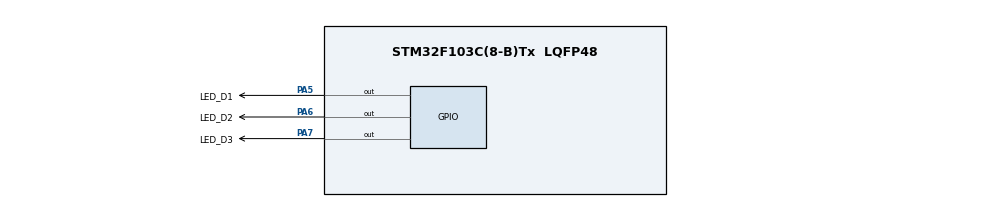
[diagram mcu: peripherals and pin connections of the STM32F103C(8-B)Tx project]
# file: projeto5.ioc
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Mcu.Family=STM32F1
Mcu.Name=STM32F103C(8-B)Tx
Mcu.Package=LQFP48
NVIC.PriorityGroup=NVIC_PRIORITYGROUP_4
NVIC.TIM1_BRK_IRQn=true\:0\:0\:false\:false\:true\:true\:true
NVIC.TIM1_UP_IRQn=true\:0\:0\:false\:false\:true\:true\:true
NVIC.TIM2_IRQn=true\:0\:0\:false\:false\:true\:true\:true
NVIC.TIM3_IRQn=true\:0\:0\:false\:false\:true\:true\:true
PA13.Mode=Serial_Wire
PA13.Signal=SYS_JTMS-SWDIO
PA14.Mode=Serial_Wire
PA14.Signal=SYS_JTCK-SWCLK
PA5.GPIO_Label=LED_D1
PA5.Signal=GPIO_Output
PA6.GPIO_Label=LED_D2
PA6.Signal=GPIO_Output
PA7.GPIO_Label=LED_D3
PA7.Signal=GPIO_Output
ProjectManager.HeapSize=0x200
ProjectManager.StackSize=0x400
ProjectManager.TargetToolchain=SW4STM32
RCC.APB1Freq_Value=8000000
RCC.APB2Freq_Value=8000000
TIM1.Period=9999
TIM1.Prescaler=799
TIM2.Period=9999
TIM2.Prescaler=1599
TIM3.Period=8000
TIM3.Prescaler=3199
VP_TIM1_VS_ClockSourceINT.Mode=Internal
VP_TIM2_VS_ClockSourceINT.Mode=Internal
VP_TIM3_VS_ClockSourceINT.Mode=Internal
board=custom

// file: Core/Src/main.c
/* USER CODE BEGIN Header */
/**
  ******************************************************************************
  * @file           : main.c
  * @brief          : Main program body
  ******************************************************************************
  * @attention
  *
  * <h2><center>&copy; Copyright (c) 2021 STMicroelectronics.
  * All rights reserved.</center></h2>
  *
  * This software component is licensed by ST under BSD 3-Clause license,
  * the "License"; You may not use this file except in compliance with the
  * License. You may obtain a copy of the License at:
  *                        opensource.org/licenses/BSD-3-Clause
  *
  ******************************************************************************
  */
/* USER CODE END Header */
#include "main.h"

TIM_HandleTypeDef htim1;
TIM_HandleTypeDef htim2;
TIM_HandleTypeDef htim3;

void SystemClock_Config(void);
static void MX_GPIO_Init(void);
static void MX_TIM1_Init(void);
static void MX_TIM2_Init(void);
static void MX_TIM3_Init(void);

int main(void)
{

  /* MCU Configuration--------------------------------------------------------*/

  /* Reset of all peripherals, Initializes the Flash interface and the Systick. */
  HAL_Init();

  /* Configure the system clock */
  SystemClock_Config();

  /* USER CODE BEGIN SysInit */
  HAL_GPIO_TogglePin(GPIOA, LED_D1_Pin);
  /* USER CODE END SysInit */

  /* Initialize all configured peripherals */
  MX_GPIO_Init();
  MX_TIM1_Init();
  MX_TIM2_Init();
  MX_TIM3_Init();
  /* USER CODE BEGIN 2 */
  HAL_TIM_Base_Start_IT(&htim3);
  HAL_TIM_Base_Start_IT(&htim2);
  HAL_TIM_Base_Start_IT(&htim1);
  /* USER CODE END 2 */

  /* Infinite loop */
  while (1)
  {

  }
}

void SystemClock_Config(void)
{
  RCC_OscInitTypeDef RCC_OscInitStruct = {0};
  RCC_ClkInitTypeDef RCC_ClkInitStruct = {0};

  /** Initializes the RCC Oscillators according to the specified parameters
  * in the RCC_OscInitTypeDef structure.
  */
  RCC_OscInitStruct.OscillatorType = RCC_OSCILLATORTYPE_HSI;
  RCC_OscInitStruct.HSIState = RCC_HSI_ON;
  RCC_OscInitStruct.HSICalibrationValue = RCC_HSICALIBRATION_DEFAULT;
  RCC_OscInitStruct.PLL.PLLState = RCC_PLL_NONE;
  if (HAL_RCC_OscConfig(&RCC_OscInitStruct) != HAL_OK)
  {
    Error_Handler();
  }
  /** Initializes the CPU, AHB and APB buses clocks
  */
  RCC_ClkInitStruct.ClockType = RCC_CLOCKTYPE_HCLK|RCC_CLOCKTYPE_SYSCLK
                              |RCC_CLOCKTYPE_PCLK1|RCC_CLOCKTYPE_PCLK2;
  RCC_ClkInitStruct.SYSCLKSource = RCC_SYSCLKSOURCE_HSI;
  RCC_ClkInitStruct.AHBCLKDivider = RCC_SYSCLK_DIV1;
  RCC_ClkInitStruct.APB1CLKDivider = RCC_HCLK_DIV1;
  RCC_ClkInitStruct.APB2CLKDivider = RCC_HCLK_DIV1;

  if (HAL_RCC_ClockConfig(&RCC_ClkInitStruct, FLASH_LATENCY_0) != HAL_OK)
  {
    Error_Handler();
  }
}

static void MX_TIM1_Init(void)
{

  TIM_ClockConfigTypeDef sClockSourceConfig = {0};
  TIM_MasterConfigTypeDef sMasterConfig = {0};

  htim1.Instance = TIM1;
  htim1.Init.Prescaler = 799;
  htim1.Init.CounterMode = TIM_COUNTERMODE_UP;
  htim1.Init.Period = 9999;
  htim1.Init.ClockDivision = TIM_CLOCKDIVISION_DIV1;
  htim1.Init.RepetitionCounter = 0;
  htim1.Init.AutoReloadPreload = TIM_AUTORELOAD_PRELOAD_DISABLE;
  if (HAL_TIM_Base_Init(&htim1) != HAL_OK)
  {
    Error_Handler();
  }
  sClockSourceConfig.ClockSource = TIM_CLOCKSOURCE_INTERNAL;
  if (HAL_TIM_ConfigClockSource(&htim1, &sClockSourceConfig) != HAL_OK)
  {
    Error_Handler();
  }
  sMasterConfig.MasterOutputTrigger = TIM_TRGO_RESET;
  sMasterConfig.MasterSlaveMode = TIM_MASTERSLAVEMODE_DISABLE;
  if (HAL_TIMEx_MasterConfigSynchronization(&htim1, &sMasterConfig) != HAL_OK)
  {
    Error_Handler();
  }

}

static void MX_TIM2_Init(void)
{

  TIM_ClockConfigTypeDef sClockSourceConfig = {0};
  TIM_MasterConfigTypeDef sMasterConfig = {0};

  htim2.Instance = TIM2;
  htim2.Init.Prescaler = 1599;
  htim2.Init.CounterMode = TIM_COUNTERMODE_UP;
  htim2.Init.Period = 9999;
  htim2.Init.ClockDivision = TIM_CLOCKDIVISION_DIV1;
  htim2.Init.AutoReloadPreload = TIM_AUTORELOAD_PRELOAD_DISABLE;
  if (HAL_TIM_Base_Init(&htim2) != HAL_OK)
  {
    Error_Handler();
  }
  sClockSourceConfig.ClockSource = TIM_CLOCKSOURCE_INTERNAL;
  if (HAL_TIM_ConfigClockSource(&htim2, &sClockSourceConfig) != HAL_OK)
  {
    Error_Handler();
  }
  sMasterConfig.MasterOutputTrigger = TIM_TRGO_RESET;
  sMasterConfig.MasterSlaveMode = TIM_MASTERSLAVEMODE_DISABLE;
  if (HAL_TIMEx_MasterConfigSynchronization(&htim2, &sMasterConfig) != HAL_OK)
  {
    Error_Handler();
  }

}

static void MX_TIM3_Init(void)
{

  TIM_ClockConfigTypeDef sClockSourceConfig = {0};
  TIM_MasterConfigTypeDef sMasterConfig = {0};

  htim3.Instance = TIM3;
  htim3.Init.Prescaler = 3199;
  htim3.Init.CounterMode = TIM_COUNTERMODE_UP;
  htim3.Init.Period = 8000;
  htim3.Init.ClockDivision = TIM_CLOCKDIVISION_DIV1;
  htim3.Init.AutoReloadPreload = TIM_AUTORELOAD_PRELOAD_DISABLE;
  if (HAL_TIM_Base_Init(&htim3) != HAL_OK)
  {
    Error_Handler();
  }
  sClockSourceConfig.ClockSource = TIM_CLOCKSOURCE_INTERNAL;
  if (HAL_TIM_ConfigClockSource(&htim3, &sClockSourceConfig) != HAL_OK)
  {
    Error_Handler();
  }
  sMasterConfig.MasterOutputTrigger = TIM_TRGO_RESET;
  sMasterConfig.MasterSlaveMode = TIM_MASTERSLAVEMODE_DISABLE;
  if (HAL_TIMEx_MasterConfigSynchronization(&htim3, &sMasterConfig) != HAL_OK)
  {
    Error_Handler();
  }

}

static void MX_GPIO_Init(void)
{
  GPIO_InitTypeDef GPIO_InitStruct = {0};

  /* GPIO Ports Clock Enable */
  __HAL_RCC_GPIOA_CLK_ENABLE();

  /*Configure GPIO pin Output Level */
  HAL_GPIO_WritePin(GPIOA, LED_D1_Pin|LED_D2_Pin|LED_D3_Pin, GPIO_PIN_RESET);

  /*Configure GPIO pins : LED_D1_Pin LED_D2_Pin LED_D3_Pin */
  GPIO_InitStruct.Pin = LED_D1_Pin|LED_D2_Pin|LED_D3_Pin;
  GPIO_InitStruct.Mode = GPIO_MODE_OUTPUT_PP;
  GPIO_InitStruct.Pull = GPIO_NOPULL;
  GPIO_InitStruct.Speed = GPIO_SPEED_FREQ_LOW;
  HAL_GPIO_Init(GPIOA, &GPIO_InitStruct);

}

void Error_Handler(void)
{
  __disable_irq();
  while (1)
  {
  }
}

/************************ (C) COPYRIGHT STMicroelectronics *****END OF FILE****/
